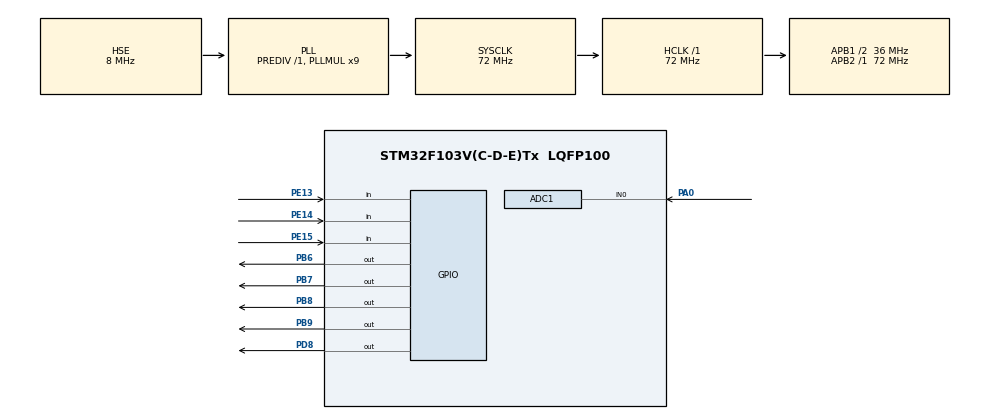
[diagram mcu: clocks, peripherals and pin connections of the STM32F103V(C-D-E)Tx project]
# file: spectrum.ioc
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ADC1.Channel-2\#ChannelRegularConversion=ADC_CHANNEL_0
ADC1.ExternalTrigConv=ADC_EXTERNALTRIGCONV_T3_TRGO
ADC1.NbrOfConversionFlag=1
ADC1.Rank-2\#ChannelRegularConversion=1
ADC1.SamplingTime-2\#ChannelRegularConversion=ADC_SAMPLETIME_71CYCLES_5
ADC1.master=1
Dma.ADC1.0.Direction=DMA_PERIPH_TO_MEMORY
Dma.ADC1.0.Instance=DMA1_Channel1
Dma.ADC1.0.MemDataAlignment=DMA_MDATAALIGN_HALFWORD
Dma.ADC1.0.MemInc=DMA_MINC_ENABLE
Dma.ADC1.0.Mode=DMA_CIRCULAR
Dma.ADC1.0.PeriphDataAlignment=DMA_PDATAALIGN_HALFWORD
Dma.ADC1.0.PeriphInc=DMA_PINC_DISABLE
Dma.ADC1.0.Priority=DMA_PRIORITY_HIGH
Dma.Request0=ADC1
Mcu.Family=STM32F1
Mcu.Name=STM32F103V(C-D-E)Tx
Mcu.Package=LQFP100
NVIC.DMA1_Channel1_IRQn=true\:0\:0\:false\:false\:true\:false\:true\:true
NVIC.PriorityGroup=NVIC_PRIORITYGROUP_4
OSC_IN.Mode=HSE-External-Oscillator
OSC_IN.Signal=RCC_OSC_IN
OSC_OUT.Mode=HSE-External-Oscillator
OSC_OUT.Signal=RCC_OSC_OUT
PA0-WKUP.Signal=ADCx_IN0
PA13.Mode=Serial_Wire
PA13.Signal=SYS_JTMS-SWDIO
PA14.Mode=Serial_Wire
PA14.Signal=SYS_JTCK-SWCLK
PB6.PinState=GPIO_PIN_SET
PB6.Signal=GPIO_Output
PB7.PinState=GPIO_PIN_SET
PB7.Signal=GPIO_Output
PB8.GPIO_ModeDefaultOutputPP=GPIO_MODE_OUTPUT_OD
PB8.GPIO_PuPd=GPIO_NOPULL
PB8.GPIO_Speed=GPIO_SPEED_FREQ_MEDIUM
PB8.PinState=GPIO_PIN_SET
PB8.Signal=GPIO_Output
PB9.GPIO_ModeDefaultOutputPP=GPIO_MODE_OUTPUT_OD
PB9.GPIO_PuPd=GPIO_NOPULL
PB9.GPIO_Speed=GPIO_SPEED_FREQ_MEDIUM
PB9.PinState=GPIO_PIN_SET
PB9.Signal=GPIO_Output
PC14-OSC32_IN.Mode=LSE-External-Oscillator
PC14-OSC32_IN.Signal=RCC_OSC32_IN
PC15-OSC32_OUT.Mode=LSE-External-Oscillator
PC15-OSC32_OUT.Signal=RCC_OSC32_OUT
PD8.PinState=GPIO_PIN_SET
PD8.Signal=GPIO_Output
PE13.GPIO_PuPd=GPIO_PULLUP
PE13.Signal=GPIO_Input
PE14.GPIO_PuPd=GPIO_PULLUP
PE14.Signal=GPIO_Input
PE15.GPIO_PuPd=GPIO_PULLUP
PE15.Signal=GPIO_Input
ProjectManager.HeapSize=0x200
ProjectManager.StackSize=0x400
ProjectManager.TargetToolchain=MDK-ARM V5.32
RCC.ADCPresc=RCC_ADCPCLK2_DIV6
RCC.AHBFreq_Value=72000000
RCC.APB1CLKDivider=RCC_HCLK_DIV2
RCC.APB1Freq_Value=36000000
RCC.APB1TimFreq_Value=72000000
RCC.APB2Freq_Value=72000000
RCC.APB2TimFreq_Value=72000000
RCC.HCLKFreq_Value=72000000
RCC.PLLMUL=RCC_PLL_MUL9
RCC.PLLSourceVirtual=RCC_PLLSOURCE_HSE
RCC.SYSCLKFreq_VALUE=72000000
RCC.SYSCLKSource=RCC_SYSCLKSOURCE_PLLCLK
RCC.USBFreq_Value=72000000
SH.ADCx_IN0.0=ADC1_IN0,IN0
STMicroelectronics.X-CUBE-ALGOBUILD.1.4.0.LibraryCcDSPOoLibraryJjDSPOoLibrary=true
TIM3.Period=1124
TIM3.TIM_MasterOutputTrigger=TIM_TRGO_UPDATE
VP_STMicroelectronics.X-CUBE-ALGOBUILD_VS_DSPOoLibraryJjLibrary_1.4.0_1.4.0.Mode=DSPOoLibraryJjLibrary
VP_TIM3_VS_ClockSourceINT.Mode=Internal
board=custom

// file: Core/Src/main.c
/* USER CODE BEGIN Header */
/**
  ******************************************************************************
  * @file           : main.c
  * @brief          : Main program body
  ******************************************************************************
  * @attention
  *
  * Copyright (c) 2026 STMicroelectronics.
  * All rights reserved.
  *
  * This software is licensed under terms that can be found in the LICENSE file
  * in the root directory of this software component.
  * If no LICENSE file comes with this software, it is provided AS-IS.
  *
  ******************************************************************************
  */
/* USER CODE END Header */
#include "main.h"

/* USER CODE BEGIN Includes */
#include "app.h"
/* USER CODE END Includes */

ADC_HandleTypeDef hadc1;
DMA_HandleTypeDef hdma_adc1;

TIM_HandleTypeDef htim3;

void SystemClock_Config(void);
static void MX_GPIO_Init(void);
static void MX_DMA_Init(void);
static void MX_ADC1_Init(void);
static void MX_TIM3_Init(void);
/* USER CODE BEGIN PFP */
void App_Init(void);
void App_Loop(void);
/* USER CODE END PFP */

int main(void)
{

  /* MCU Configuration--------------------------------------------------------*/

  /* Reset of all peripherals, Initializes the Flash interface and the Systick. */
  HAL_Init();

  /* Configure the system clock */
  SystemClock_Config();

  /* Initialize all configured peripherals */
  MX_GPIO_Init();
  MX_DMA_Init();
  MX_ADC1_Init();
  MX_TIM3_Init();
  /* USER CODE BEGIN 2 */
  App_Init();

  /* USER CODE END 2 */

  /* Infinite loop */
  /* USER CODE BEGIN WHILE */
  while (1)
  {
    App_Loop();
    /* USER CODE END WHILE */

  }
}

void SystemClock_Config(void)
{
  RCC_OscInitTypeDef RCC_OscInitStruct = {0};
  RCC_ClkInitTypeDef RCC_ClkInitStruct = {0};
  RCC_PeriphCLKInitTypeDef PeriphClkInit = {0};

  /** Initializes the RCC Oscillators according to the specified parameters
  * in the RCC_OscInitTypeDef structure.
  */
  RCC_OscInitStruct.OscillatorType = RCC_OSCILLATORTYPE_HSE;
  RCC_OscInitStruct.HSEState = RCC_HSE_ON;
  RCC_OscInitStruct.HSEPredivValue = RCC_HSE_PREDIV_DIV1;
  RCC_OscInitStruct.HSIState = RCC_HSI_ON;
  RCC_OscInitStruct.PLL.PLLState = RCC_PLL_ON;
  RCC_OscInitStruct.PLL.PLLSource = RCC_PLLSOURCE_HSE;
  RCC_OscInitStruct.PLL.PLLMUL = RCC_PLL_MUL9;
  if (HAL_RCC_OscConfig(&RCC_OscInitStruct) != HAL_OK)
  {
    Error_Handler();
  }

  /** Initializes the CPU, AHB and APB buses clocks
  */
  RCC_ClkInitStruct.ClockType = RCC_CLOCKTYPE_HCLK|RCC_CLOCKTYPE_SYSCLK
                              |RCC_CLOCKTYPE_PCLK1|RCC_CLOCKTYPE_PCLK2;
  RCC_ClkInitStruct.SYSCLKSource = RCC_SYSCLKSOURCE_PLLCLK;
  RCC_ClkInitStruct.AHBCLKDivider = RCC_SYSCLK_DIV1;
  RCC_ClkInitStruct.APB1CLKDivider = RCC_HCLK_DIV2;
  RCC_ClkInitStruct.APB2CLKDivider = RCC_HCLK_DIV1;

  if (HAL_RCC_ClockConfig(&RCC_ClkInitStruct, FLASH_LATENCY_2) != HAL_OK)
  {
    Error_Handler();
  }
  PeriphClkInit.PeriphClockSelection = RCC_PERIPHCLK_ADC;
  PeriphClkInit.AdcClockSelection = RCC_ADCPCLK2_DIV6;
  if (HAL_RCCEx_PeriphCLKConfig(&PeriphClkInit) != HAL_OK)
  {
    Error_Handler();
  }
}

static void MX_ADC1_Init(void)
{

  ADC_ChannelConfTypeDef sConfig = {0};

  /** Common config
  */
  hadc1.Instance = ADC1;
  hadc1.Init.ScanConvMode = ADC_SCAN_DISABLE;
  hadc1.Init.ContinuousConvMode = DISABLE;
  hadc1.Init.DiscontinuousConvMode = DISABLE;
  hadc1.Init.ExternalTrigConv = ADC_EXTERNALTRIGCONV_T3_TRGO;
  hadc1.Init.DataAlign = ADC_DATAALIGN_RIGHT;
  hadc1.Init.NbrOfConversion = 1;
  if (HAL_ADC_Init(&hadc1) != HAL_OK)
  {
    Error_Handler();
  }

  /** Configure Regular Channel
  */
  sConfig.Channel = ADC_CHANNEL_0;
  sConfig.Rank = ADC_REGULAR_RANK_1;
  sConfig.SamplingTime = ADC_SAMPLETIME_71CYCLES_5;
  if (HAL_ADC_ConfigChannel(&hadc1, &sConfig) != HAL_OK)
  {
    Error_Handler();
  }
  /* USER CODE BEGIN ADC1_Init 2 */
  // ADC1 is triggered by TIM3 TRGO.
  // Sampling time is 71.5 cycles; total conversion time is about
  // 71.5 + 12.5 = 84 ADC clock cycles.

  /* USER CODE END ADC1_Init 2 */

}

static void MX_TIM3_Init(void)
{

  TIM_ClockConfigTypeDef sClockSourceConfig = {0};
  TIM_MasterConfigTypeDef sMasterConfig = {0};

  htim3.Instance = TIM3;
  htim3.Init.Prescaler = 0;
  htim3.Init.CounterMode = TIM_COUNTERMODE_UP;
  htim3.Init.Period = 1124;
  htim3.Init.ClockDivision = TIM_CLOCKDIVISION_DIV1;
  htim3.Init.AutoReloadPreload = TIM_AUTORELOAD_PRELOAD_DISABLE;
  if (HAL_TIM_Base_Init(&htim3) != HAL_OK)
  {
    Error_Handler();
  }
  sClockSourceConfig.ClockSource = TIM_CLOCKSOURCE_INTERNAL;
  if (HAL_TIM_ConfigClockSource(&htim3, &sClockSourceConfig) != HAL_OK)
  {
    Error_Handler();
  }
  sMasterConfig.MasterOutputTrigger = TIM_TRGO_UPDATE;
  sMasterConfig.MasterSlaveMode = TIM_MASTERSLAVEMODE_DISABLE;
  if (HAL_TIMEx_MasterConfigSynchronization(&htim3, &sMasterConfig) != HAL_OK)
  {
    Error_Handler();
  }
  /* USER CODE BEGIN TIM3_Init 2 */
  // With TIM3 clock at 72MHz:
  // Fs = 72MHz / (Prescaler + 1) / (Period + 1)
  //    = 72MHz / 1 / 1125
  //    = 64kHz
  // Each update event is exported as TRGO to trigger one ADC conversion.

  /* USER CODE END TIM3_Init 2 */

}

static void MX_DMA_Init(void)
{

  /* DMA controller clock enable */
  __HAL_RCC_DMA1_CLK_ENABLE();

  /* DMA interrupt init */
  /* DMA1_Channel1_IRQn interrupt configuration */
  HAL_NVIC_SetPriority(DMA1_Channel1_IRQn, 0, 0);
  HAL_NVIC_EnableIRQ(DMA1_Channel1_IRQn);

}

static void MX_GPIO_Init(void)
{
  GPIO_InitTypeDef GPIO_InitStruct = {0};

  /* GPIO Ports Clock Enable */
  __HAL_RCC_GPIOC_CLK_ENABLE();
  __HAL_RCC_GPIOA_CLK_ENABLE();
  __HAL_RCC_GPIOE_CLK_ENABLE();
  __HAL_RCC_GPIOD_CLK_ENABLE();
  __HAL_RCC_GPIOB_CLK_ENABLE();

  /*Configure GPIO pin Output Level */
  HAL_GPIO_WritePin(GPIOD, GPIO_PIN_8, GPIO_PIN_SET);

  /*Configure GPIO pin Output Level */
  HAL_GPIO_WritePin(GPIOB, GPIO_PIN_6|GPIO_PIN_7|GPIO_PIN_8|GPIO_PIN_9, GPIO_PIN_SET);

  /*Configure GPIO pins : PE13 PE14 PE15 */
  GPIO_InitStruct.Pin = GPIO_PIN_13|GPIO_PIN_14|GPIO_PIN_15;
  GPIO_InitStruct.Mode = GPIO_MODE_INPUT;
  GPIO_InitStruct.Pull = GPIO_PULLUP;
  HAL_GPIO_Init(GPIOE, &GPIO_InitStruct);

  /*Configure GPIO pin : PD8 */
  GPIO_InitStruct.Pin = GPIO_PIN_8;
  GPIO_InitStruct.Mode = GPIO_MODE_OUTPUT_PP;
  GPIO_InitStruct.Pull = GPIO_NOPULL;
  GPIO_InitStruct.Speed = GPIO_SPEED_FREQ_LOW;
  HAL_GPIO_Init(GPIOD, &GPIO_InitStruct);

  /*Configure GPIO pins : PB6 PB7 */
  GPIO_InitStruct.Pin = GPIO_PIN_6|GPIO_PIN_7;
  GPIO_InitStruct.Mode = GPIO_MODE_OUTPUT_PP;
  GPIO_InitStruct.Pull = GPIO_NOPULL;
  GPIO_InitStruct.Speed = GPIO_SPEED_FREQ_LOW;
  HAL_GPIO_Init(GPIOB, &GPIO_InitStruct);

  /*Configure GPIO pins : PB8 PB9 */
  GPIO_InitStruct.Pin = GPIO_PIN_8|GPIO_PIN_9;
  GPIO_InitStruct.Mode = GPIO_MODE_OUTPUT_OD;
  GPIO_InitStruct.Pull = GPIO_NOPULL;
  GPIO_InitStruct.Speed = GPIO_SPEED_FREQ_MEDIUM;
  HAL_GPIO_Init(GPIOB, &GPIO_InitStruct);

/* USER CODE BEGIN MX_GPIO_Init_2 */
GPIO_InitStruct.Pin = GPIO_PIN_0;
GPIO_InitStruct.Mode = GPIO_MODE_ANALOG;
HAL_GPIO_Init(GPIOA, &GPIO_InitStruct);
/* USER CODE END MX_GPIO_Init_2 */
}

void Error_Handler(void)
{
  __disable_irq();
  while (1)
  {
  }
}
